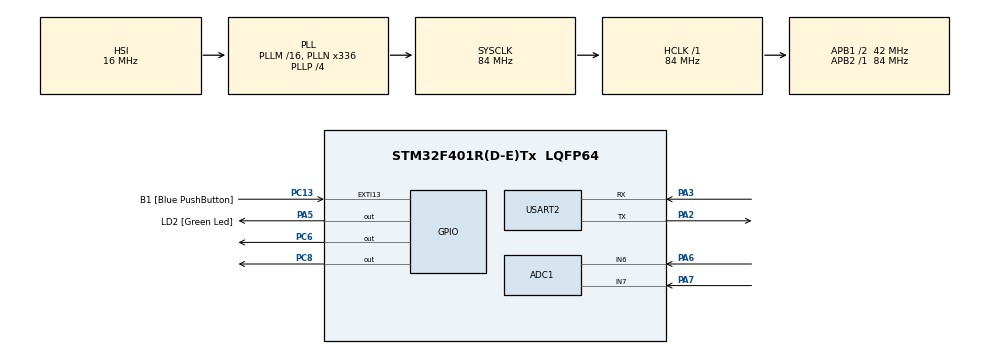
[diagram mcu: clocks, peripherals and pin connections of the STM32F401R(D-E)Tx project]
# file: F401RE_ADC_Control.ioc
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ADC1.Channel-5\#ChannelRegularConversion=ADC_CHANNEL_6
ADC1.Channel-6\#ChannelRegularConversion=ADC_CHANNEL_7
ADC1.ContinuousConvMode=ENABLE
ADC1.DMAContinuousRequests=ENABLE
ADC1.NbrOfConversion=2
ADC1.NbrOfConversionFlag=1
ADC1.Rank-5\#ChannelRegularConversion=1
ADC1.Rank-6\#ChannelRegularConversion=2
ADC1.SamplingTime-5\#ChannelRegularConversion=ADC_SAMPLETIME_144CYCLES
ADC1.SamplingTime-6\#ChannelRegularConversion=ADC_SAMPLETIME_144CYCLES
ADC1.ScanConvMode=ENABLE
ADC1.master=1
Dma.ADC1.0.Direction=DMA_PERIPH_TO_MEMORY
Dma.ADC1.0.FIFOMode=DMA_FIFOMODE_DISABLE
Dma.ADC1.0.Instance=DMA2_Stream0
Dma.ADC1.0.MemDataAlignment=DMA_MDATAALIGN_WORD
Dma.ADC1.0.MemInc=DMA_MINC_ENABLE
Dma.ADC1.0.Mode=DMA_CIRCULAR
Dma.ADC1.0.PeriphDataAlignment=DMA_PDATAALIGN_WORD
Dma.ADC1.0.PeriphInc=DMA_PINC_DISABLE
Dma.ADC1.0.Priority=DMA_PRIORITY_LOW
Dma.Request0=ADC1
Mcu.Family=STM32F4
Mcu.Name=STM32F401R(D-E)Tx
Mcu.Package=LQFP64
NVIC.DMA2_Stream0_IRQn=true\:0\:0\:false\:false\:true\:false\:true\:true
NVIC.PriorityGroup=NVIC_PRIORITYGROUP_0
PA13.GPIO_Label=TMS
PA13.Mode=Serial_Wire
PA13.Signal=SYS_JTMS-SWDIO
PA14.GPIO_Label=TCK
PA14.Mode=Serial_Wire
PA14.Signal=SYS_JTCK-SWCLK
PA2.Mode=Asynchronous
PA2.Signal=USART2_TX
PA3.Mode=Asynchronous
PA3.Signal=USART2_RX
PA5.GPIO_Label=LD2 [Green Led]
PA5.GPIO_Mode=GPIO_MODE_OUTPUT_PP
PA5.GPIO_PuPd=GPIO_NOPULL
PA5.GPIO_Speed=GPIO_SPEED_FREQ_LOW
PA5.Signal=GPIO_Output
PA6.Signal=ADCx_IN6
PA7.Signal=ADCx_IN7
PB3.GPIO_Label=SWO
PB3.Signal=SYS_JTDO-SWO
PC13-ANTI_TAMP.GPIO_Label=B1 [Blue PushButton]
PC13-ANTI_TAMP.GPIO_ModeDefaultEXTI=GPIO_MODE_IT_FALLING
PC13-ANTI_TAMP.GPIO_PuPd=GPIO_NOPULL
PC13-ANTI_TAMP.Signal=GPXTI13
PC14-OSC32_IN.Mode=LSE-External-Oscillator
PC14-OSC32_IN.Signal=RCC_OSC32_IN
PC15-OSC32_OUT.Mode=LSE-External-Oscillator
PC15-OSC32_OUT.Signal=RCC_OSC32_OUT
PC6.Signal=GPIO_Output
PC8.Signal=GPIO_Output
PH0\ -\ OSC_IN.Mode=HSE-External-Clock-Source
PH0\ -\ OSC_IN.Signal=RCC_OSC_IN
PH1\ -\ OSC_OUT.Mode=HSE-External-Clock-Source
PH1\ -\ OSC_OUT.Signal=RCC_OSC_OUT
ProjectManager.HeapSize=0x200
ProjectManager.StackSize=0x400
ProjectManager.TargetToolchain=STM32CubeIDE
RCC.48MHZClocksFreq_Value=48000000
RCC.AHBFreq_Value=84000000
RCC.APB1CLKDivider=RCC_HCLK_DIV2
RCC.APB1Freq_Value=42000000
RCC.APB1TimFreq_Value=84000000
RCC.APB2Freq_Value=84000000
RCC.APB2TimFreq_Value=84000000
RCC.CortexFreq_Value=84000000
RCC.HCLKFreq_Value=84000000
RCC.HSE_VALUE=8000000
RCC.HSI_VALUE=16000000
RCC.PLLN=336
RCC.PLLP=RCC_PLLP_DIV4
RCC.PLLQ=7
RCC.SYSCLKFreq_VALUE=84000000
RCC.SYSCLKSource=RCC_SYSCLKSOURCE_PLLCLK
RCC.VCOOutputFreq_Value=336000000
SH.ADCx_IN6.0=ADC1_IN6,IN6
SH.ADCx_IN7.0=ADC1_IN7,IN7
USART2.VirtualMode=VM_ASYNC
board=NUCLEO-F401RE

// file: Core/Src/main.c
/* USER CODE BEGIN Header */
/**
  ******************************************************************************
  * @file           : main.c
  * @brief          : Main program body
  ******************************************************************************
  * @attention
  *
  * Copyright (c) 2023 STMicroelectronics.
  * All rights reserved.
  *
  * This software is licensed under terms that can be found in the LICENSE file
  * in the root directory of this software component.
  * If no LICENSE file comes with this software, it is provided AS-IS.
  *
  ******************************************************************************
  */
/* USER CODE END Header */
#include "main.h"
#include "adc.h"
#include "dma.h"
#include "usart.h"
#include "gpio.h"

void SystemClock_Config(void);

/* USER CODE BEGIN 0 */
int __io_putchar(int ch){
	HAL_UART_Transmit(&huart2, (uint8_t *)&ch, 1, 0xFFFF);
	return ch;
}

uint32_t adc1_value[2];
/* USER CODE END 0 */

int main(void)
{

  /* MCU Configuration--------------------------------------------------------*/

  /* Reset of all peripherals, Initializes the Flash interface and the Systick. */
  HAL_Init();

  /* Configure the system clock */
  SystemClock_Config();

  /* Initialize all configured peripherals */
  MX_GPIO_Init();
  MX_DMA_Init();
  MX_USART2_UART_Init();
  MX_ADC1_Init();
  /* USER CODE BEGIN 2 */
  HAL_ADC_Start_DMA(&hadc1, (uint32_t *)adc1_value, 2);
  /* USER CODE END 2 */

  /* Infinite loop */
  /* USER CODE BEGIN WHILE */
  while (1)
  {
	  printf("val0 = %ld, val1 = %ld\n", adc1_value[0], adc1_value[1]);
	  HAL_Delay(1000);
    /* USER CODE END WHILE */

  }
}

void SystemClock_Config(void)
{
  RCC_OscInitTypeDef RCC_OscInitStruct = {0};
  RCC_ClkInitTypeDef RCC_ClkInitStruct = {0};

  /** Configure the main internal regulator output voltage
  */
  __HAL_RCC_PWR_CLK_ENABLE();
  __HAL_PWR_VOLTAGESCALING_CONFIG(PWR_REGULATOR_VOLTAGE_SCALE2);

  /** Initializes the RCC Oscillators according to the specified parameters
  * in the RCC_OscInitTypeDef structure.
  */
  RCC_OscInitStruct.OscillatorType = RCC_OSCILLATORTYPE_HSI;
  RCC_OscInitStruct.HSIState = RCC_HSI_ON;
  RCC_OscInitStruct.HSICalibrationValue = RCC_HSICALIBRATION_DEFAULT;
  RCC_OscInitStruct.PLL.PLLState = RCC_PLL_ON;
  RCC_OscInitStruct.PLL.PLLSource = RCC_PLLSOURCE_HSI;
  RCC_OscInitStruct.PLL.PLLM = 16;
  RCC_OscInitStruct.PLL.PLLN = 336;
  RCC_OscInitStruct.PLL.PLLP = RCC_PLLP_DIV4;
  RCC_OscInitStruct.PLL.PLLQ = 7;
  if (HAL_RCC_OscConfig(&RCC_OscInitStruct) != HAL_OK)
  {
    Error_Handler();
  }

  /** Initializes the CPU, AHB and APB buses clocks
  */
  RCC_ClkInitStruct.ClockType = RCC_CLOCKTYPE_HCLK|RCC_CLOCKTYPE_SYSCLK
                              |RCC_CLOCKTYPE_PCLK1|RCC_CLOCKTYPE_PCLK2;
  RCC_ClkInitStruct.SYSCLKSource = RCC_SYSCLKSOURCE_PLLCLK;
  RCC_ClkInitStruct.AHBCLKDivider = RCC_SYSCLK_DIV1;
  RCC_ClkInitStruct.APB1CLKDivider = RCC_HCLK_DIV2;
  RCC_ClkInitStruct.APB2CLKDivider = RCC_HCLK_DIV1;

  if (HAL_RCC_ClockConfig(&RCC_ClkInitStruct, FLASH_LATENCY_2) != HAL_OK)
  {
    Error_Handler();
  }
}

void Error_Handler(void)
{
  __disable_irq();
  while (1)
  {
  }
}
